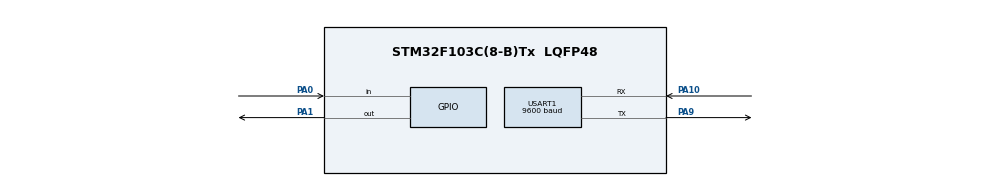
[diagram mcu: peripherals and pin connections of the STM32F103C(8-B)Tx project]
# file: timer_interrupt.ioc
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Mcu.Family=STM32F1
Mcu.Name=STM32F103C(8-B)Tx
Mcu.Package=LQFP48
NVIC.PriorityGroup=NVIC_PRIORITYGROUP_4
NVIC.TIM3_IRQn=true\:0\:0\:false\:false\:true\:true\:true\:true
PA0-WKUP.GPIO_PuPd=GPIO_PULLDOWN
PA0-WKUP.Signal=GPIO_Input
PA1.Signal=GPIO_Output
PA10.Mode=Asynchronous
PA10.Signal=USART1_RX
PA9.Mode=Asynchronous
PA9.Signal=USART1_TX
ProjectManager.HeapSize=0x200
ProjectManager.StackSize=0x400
ProjectManager.TargetToolchain=STM32CubeIDE
RCC.APB1Freq_Value=8000000
RCC.APB2Freq_Value=8000000
TIM3.Period=999
TIM3.Prescaler=7999
USART1.BaudRate=9600
USART1.VirtualMode=VM_ASYNC
VP_SYS_VS_ND.Mode=No_Debug
VP_TIM3_VS_ClockSourceINT.Mode=Internal
board=custom

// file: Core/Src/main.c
/* USER CODE BEGIN Header */
/**
  ******************************************************************************
  * @file           : main.c
  * @brief          : Main program body
  ******************************************************************************
  * @attention
  *
  * Copyright (c) 2026 STMicroelectronics.
  * All rights reserved.
  *
  * This software is licensed under terms that can be found in the LICENSE file
  * in the root directory of this software component.
  * If no LICENSE file comes with this software, it is provided AS-IS.
  *
  ******************************************************************************
  */
/* USER CODE END Header */

#include "main.h"
#include <string.h>

TIM_HandleTypeDef htim3;

UART_HandleTypeDef huart1;

void SystemClock_Config(void);
static void MX_GPIO_Init(void);
static void MX_TIM3_Init(void);
static void MX_USART1_UART_Init(void);

/* USER CODE BEGIN 0 */

uint8_t present_flag = 0;
uint8_t seconds_count = 0;
char msg[] = "Ongoing Task\n";
char msg1[] = "Done\n";

/* USER CODE END 0 */

void HAL_TIM_PeriodElapsedCallback(TIM_HandleTypeDef *htim){
	if(htim->Instance == TIM3 && present_flag){
		if(HAL_GPIO_ReadPin(GPIOA, GPIO_PIN_0) == GPIO_PIN_RESET){
			HAL_TIM_Base_Stop_IT(&htim3);
			HAL_GPIO_WritePin(GPIOA, GPIO_PIN_1, GPIO_PIN_RESET);
			present_flag = 0;
			seconds_count = 0;

		}
		else{
			seconds_count++;
			if(seconds_count >1){
				HAL_TIM_Base_Stop_IT(&htim3);
				HAL_GPIO_WritePin(GPIOA, GPIO_PIN_1, GPIO_PIN_SET);
				present_flag = 0;
				seconds_count = 0;
			}
		}
	}
}
int main(void)
{

  /* MCU Configuration--------------------------------------------------------*/

  /* Reset of all peripherals, Initializes the Flash interface and the Systick. */
  HAL_Init();

  /* Configure the system clock */
  SystemClock_Config();

  /* Initialize all configured peripherals */
  MX_GPIO_Init();
  MX_TIM3_Init();
  MX_USART1_UART_Init();

  /* Infinite loop */
  while (1)
  {
	  if (HAL_GPIO_ReadPin(GPIOA, GPIO_PIN_0) == GPIO_PIN_SET && present_flag == 0 ){

		  present_flag =1;
		  HAL_TIM_Base_Start_IT(&htim3); //when switch pressed then timer will start and will count upto 1sec as we wrote in the counter in ioc file and this will go on behind all work is going on
		  // after this void HAL_TIM_PeriodElapsedCallback(TIM_HandleTypeDef *htim) will be called after completing 1 seconds as set by the user
		  HAL_UART_Transmit(&huart1, (uint8_t *)msg1, strlen(msg1), 100);

	  }
    /* USER CODE BEGIN 3 */
	  HAL_UART_Transmit(&huart1, (uint8_t *)msg, strlen(msg), 100);
	  HAL_Delay(50);
    /* USER CODE BEGIN 3 */
  }
  /* USER CODE END 3 */
}

void SystemClock_Config(void)
{
  RCC_OscInitTypeDef RCC_OscInitStruct = {0};
  RCC_ClkInitTypeDef RCC_ClkInitStruct = {0};

  /** Initializes the RCC Oscillators according to the specified parameters
  * in the RCC_OscInitTypeDef structure.
  */
  RCC_OscInitStruct.OscillatorType = RCC_OSCILLATORTYPE_HSI;
  RCC_OscInitStruct.HSIState = RCC_HSI_ON;
  RCC_OscInitStruct.HSICalibrationValue = RCC_HSICALIBRATION_DEFAULT;
  RCC_OscInitStruct.PLL.PLLState = RCC_PLL_NONE;
  if (HAL_RCC_OscConfig(&RCC_OscInitStruct) != HAL_OK)
  {
    Error_Handler();
  }

  /** Initializes the CPU, AHB and APB buses clocks
  */
  RCC_ClkInitStruct.ClockType = RCC_CLOCKTYPE_HCLK|RCC_CLOCKTYPE_SYSCLK
                              |RCC_CLOCKTYPE_PCLK1|RCC_CLOCKTYPE_PCLK2;
  RCC_ClkInitStruct.SYSCLKSource = RCC_SYSCLKSOURCE_HSI;
  RCC_ClkInitStruct.AHBCLKDivider = RCC_SYSCLK_DIV1;
  RCC_ClkInitStruct.APB1CLKDivider = RCC_HCLK_DIV1;
  RCC_ClkInitStruct.APB2CLKDivider = RCC_HCLK_DIV1;

  if (HAL_RCC_ClockConfig(&RCC_ClkInitStruct, FLASH_LATENCY_0) != HAL_OK)
  {
    Error_Handler();
  }
}

static void MX_TIM3_Init(void)
{

  TIM_ClockConfigTypeDef sClockSourceConfig = {0};
  TIM_MasterConfigTypeDef sMasterConfig = {0};

  htim3.Instance = TIM3;
  htim3.Init.Prescaler = 7999;
  htim3.Init.CounterMode = TIM_COUNTERMODE_UP;
  htim3.Init.Period = 999;
  htim3.Init.ClockDivision = TIM_CLOCKDIVISION_DIV1;
  htim3.Init.AutoReloadPreload = TIM_AUTORELOAD_PRELOAD_DISABLE;
  if (HAL_TIM_Base_Init(&htim3) != HAL_OK)
  {
    Error_Handler();
  }
  sClockSourceConfig.ClockSource = TIM_CLOCKSOURCE_INTERNAL;
  if (HAL_TIM_ConfigClockSource(&htim3, &sClockSourceConfig) != HAL_OK)
  {
    Error_Handler();
  }
  sMasterConfig.MasterOutputTrigger = TIM_TRGO_RESET;
  sMasterConfig.MasterSlaveMode = TIM_MASTERSLAVEMODE_DISABLE;
  if (HAL_TIMEx_MasterConfigSynchronization(&htim3, &sMasterConfig) != HAL_OK)
  {
    Error_Handler();
  }

}

static void MX_USART1_UART_Init(void)
{

  huart1.Instance = USART1;
  huart1.Init.BaudRate = 9600;
  huart1.Init.WordLength = UART_WORDLENGTH_8B;
  huart1.Init.StopBits = UART_STOPBITS_1;
  huart1.Init.Parity = UART_PARITY_NONE;
  huart1.Init.Mode = UART_MODE_TX_RX;
  huart1.Init.HwFlowCtl = UART_HWCONTROL_NONE;
  huart1.Init.OverSampling = UART_OVERSAMPLING_16;
  if (HAL_UART_Init(&huart1) != HAL_OK)
  {
    Error_Handler();
  }

}

static void MX_GPIO_Init(void)
{
  GPIO_InitTypeDef GPIO_InitStruct = {0};

  /* GPIO Ports Clock Enable */
  __HAL_RCC_GPIOA_CLK_ENABLE();

  /*Configure GPIO pin Output Level */
  HAL_GPIO_WritePin(GPIOA, GPIO_PIN_1, GPIO_PIN_RESET);

  /*Configure GPIO pin : PA0 */
  GPIO_InitStruct.Pin = GPIO_PIN_0;
  GPIO_InitStruct.Mode = GPIO_MODE_INPUT;
  GPIO_InitStruct.Pull = GPIO_PULLDOWN;
  HAL_GPIO_Init(GPIOA, &GPIO_InitStruct);

  /*Configure GPIO pin : PA1 */
  GPIO_InitStruct.Pin = GPIO_PIN_1;
  GPIO_InitStruct.Mode = GPIO_MODE_OUTPUT_PP;
  GPIO_InitStruct.Pull = GPIO_NOPULL;
  GPIO_InitStruct.Speed = GPIO_SPEED_FREQ_LOW;
  HAL_GPIO_Init(GPIOA, &GPIO_InitStruct);

}

void Error_Handler(void)
{
  __disable_irq();
  while (1)
  {
  }
}
